# STM32C031 register map
Registers are access not given, no defined reset value unless marked. A register's access mark holds for its fields unless they carry their own. Offsets are from the block's base; lines under a group give offsets from that group; [hi:lo] are bit positions; {n}, {i} and the like mark numbered series; 'fields as' and 'values as' point back to an identical list; <NAME> marks a mode.

## Memory map
? FLASH

## FLASH
Base ?
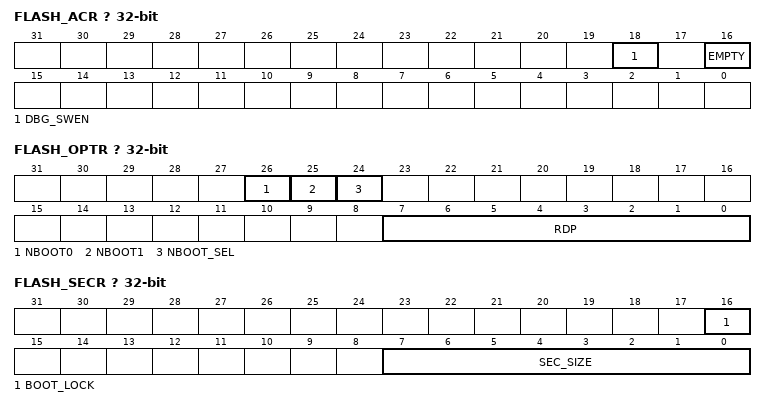
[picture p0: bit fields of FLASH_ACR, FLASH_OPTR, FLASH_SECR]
? FLASH_ACR — Flash access control register
  [18] DBG_SWEN — Debug access software enable Software may use this bit to enable/disable the debugger read access.
    0=Debugger disabled; 1=Debugger enabled
  [16] EMPTY — Main flash memory area empty
? FLASH_OPTR — Flash option register
  [26] NBOOT0 — nBOOT0 option bit
    0=nBOOT0=0; 1=nBOOT0=1
  [25] NBOOT1 — Boot configuration Together with the BOOT0 pin or option bit nBOOT0 (depending on nBOOT_SEL option bit configuration), this bit selects boot mode from the Main flash memory, SRAM or the System memory. Refer to Section3: Boot configuration.
  [24] NBOOT_SEL — BOOT0 signal source selection This option bit defines the source of the BOOT0 signal.
    0=BOOT0 pin (legacy mode); 1=nBOOT0 option bit
  [7:0] RDP — Read protection level Other: Level 1, memories read protection active
    170=Level 0, read protection not active; 204=Level 2, chip read protection active
? FLASH_SECR — Flash security register
  [16] BOOT_LOCK — used to force boot from user area If the bit is set in association with RDP level 1, the debug capabilities are disabled
  [7:0] SEC_SIZE — Securable memory area size
